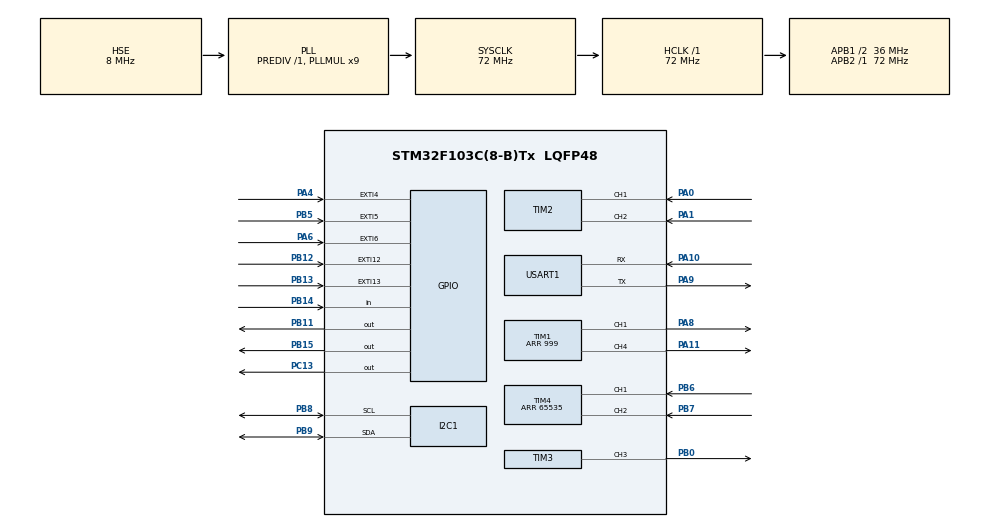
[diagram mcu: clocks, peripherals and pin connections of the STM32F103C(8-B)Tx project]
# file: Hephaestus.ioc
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FREERTOS.Tasks01=defaultTask,24,128,StartDefaultTask,Default,NULL,Dynamic,NULL,NULL
FREERTOS.configTOTAL_HEAP_SIZE=10240
I2C1.I2C_Mode=I2C_Standard
IWDG.Prescaler=IWDG_PRESCALER_32
IWDG.Reload=625
Mcu.Family=STM32F1
Mcu.Name=STM32F103C(8-B)Tx
Mcu.Package=LQFP48
NVIC.EXTI15_10_IRQn=true\:5\:0\:false\:false\:true\:false\:true\:true\:true
NVIC.EXTI4_IRQn=true\:5\:0\:false\:false\:true\:false\:true\:true\:true
NVIC.EXTI9_5_IRQn=true\:5\:0\:false\:false\:true\:false\:true\:true\:true
NVIC.PriorityGroup=NVIC_PRIORITYGROUP_4
PA0-WKUP.Signal=S_TIM2_CH1_ETR
PA1.Signal=S_TIM2_CH2
PA10.Mode=Asynchronous
PA10.Signal=USART1_RX
PA11.Signal=S_TIM1_CH4
PA13.Mode=Serial_Wire
PA13.Signal=SYS_JTMS-SWDIO
PA14.Mode=Serial_Wire
PA14.Signal=SYS_JTCK-SWCLK
PA4.GPIO_PuPd=GPIO_PULLUP
PA4.Signal=GPXTI4
PA6.GPIO_PuPd=GPIO_PULLUP
PA6.Signal=GPXTI6
PA8.Signal=S_TIM1_CH1
PA9.Mode=Asynchronous
PA9.Signal=USART1_TX
PB0.Signal=S_TIM3_CH3
PB11.Signal=GPIO_Output
PB12.GPIO_PuPd=GPIO_PULLUP
PB12.Signal=GPXTI12
PB13.GPIO_PuPd=GPIO_PULLUP
PB13.Signal=GPXTI13
PB14.GPIO_PuPd=GPIO_NOPULL
PB14.Signal=GPIO_Input
PB15.Signal=GPIO_Output
PB5.Signal=GPXTI5
PB6.Signal=S_TIM4_CH1
PB7.Signal=S_TIM4_CH2
PB8.Mode=I2C
PB8.Signal=I2C1_SCL
PB9.Mode=I2C
PB9.Signal=I2C1_SDA
PC13-TAMPER-RTC.Signal=GPIO_Output
PD0-OSC_IN.Mode=HSE-External-Oscillator
PD0-OSC_IN.Signal=RCC_OSC_IN
PD1-OSC_OUT.Mode=HSE-External-Oscillator
PD1-OSC_OUT.Signal=RCC_OSC_OUT
ProjectManager.HeapSize=0x200
ProjectManager.StackSize=0x400
ProjectManager.TargetToolchain=CMake
RCC.AHBFreq_Value=72000000
RCC.APB1CLKDivider=RCC_HCLK_DIV2
RCC.APB1Freq_Value=36000000
RCC.APB1TimFreq_Value=72000000
RCC.APB2Freq_Value=72000000
RCC.APB2TimFreq_Value=72000000
RCC.HCLKFreq_Value=72000000
RCC.PLLMUL=RCC_PLL_MUL9
RCC.PLLSourceVirtual=RCC_PLLSOURCE_HSE
RCC.SYSCLKFreq_VALUE=72000000
RCC.SYSCLKSource=RCC_SYSCLKSOURCE_PLLCLK
RCC.USBFreq_Value=72000000
SH.S_TIM1_CH1.0=TIM1_CH1,PWM Generation1 CH1
SH.S_TIM1_CH4.0=TIM1_CH4,PWM Generation4 CH4
SH.S_TIM2_CH1_ETR.0=TIM2_CH1,Encoder_Interface
SH.S_TIM2_CH2.0=TIM2_CH2,Encoder_Interface
SH.S_TIM3_CH3.0=TIM3_CH3,PWM Generation3 CH3
SH.S_TIM4_CH1.0=TIM4_CH1,Encoder_Interface
SH.S_TIM4_CH2.0=TIM4_CH2,Encoder_Interface
TIM1.Channel-PWM\ Generation1\ CH1=TIM_CHANNEL_1
TIM1.Channel-PWM\ Generation4\ CH4=TIM_CHANNEL_4
TIM1.Period=999
TIM2.EncoderMode=TIM_ENCODERMODE_TI12
TIM3.Channel-PWM\ Generation3\ CH3=TIM_CHANNEL_3
TIM3.Period=249
TIM3.Prescaler=71
TIM4.EncoderMode=TIM_ENCODERMODE_TI12
TIM4.Period=65535
USART1.VirtualMode=VM_ASYNC
VP_FREERTOS_VS_CMSIS_V2.Mode=CMSIS_V2
VP_IWDG_VS_IWDG.Mode=IWDG_Activate
board=custom

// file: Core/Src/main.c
/* USER CODE BEGIN Header */
/**
  ******************************************************************************
  * @file           : main.c
  * @brief          : Main program body
  ******************************************************************************
  * @attention
  *
  * Copyright (c) 2026 STMicroelectronics.
  * All rights reserved.
  *
  * This software is licensed under terms that can be found in the LICENSE file
  * in the root directory of this software component.
  * If no LICENSE file comes with this software, it is provided AS-IS.
  *
  ******************************************************************************
  */
/* USER CODE END Header */
#include "main.h"
#include "cmsis_os.h"
#include "i2c.h"
#include "iwdg.h"
#include "tim.h"
#include "usart.h"
#include "gpio.h"

/* USER CODE BEGIN Includes */
#include "app.hpp"
/* USER CODE END Includes */

void SystemClock_Config(void);
void MX_FREERTOS_Init(void);

int main(void)
{

  /* MCU Configuration--------------------------------------------------------*/

  /* Reset of all peripherals, Initializes the Flash interface and the Systick. */
  HAL_Init();

  /* Configure the system clock */
  SystemClock_Config();

  /* Initialize all configured peripherals */
  MX_GPIO_Init();
  MX_I2C1_Init();
  MX_TIM1_Init();
  MX_TIM2_Init();
  MX_TIM3_Init();
  MX_TIM4_Init();
  MX_USART1_UART_Init();
  MX_IWDG_Init();
  /* USER CODE BEGIN 2 */
  app_setup();
  /* USER CODE END 2 */

  /* Init scheduler */
  osKernelInitialize();  /* Call init function for freertos objects (in cmsis_os2.c) */
  MX_FREERTOS_Init();

  /* Start scheduler */
  osKernelStart();

  /* We should never get here as control is now taken by the scheduler */

  /* Infinite loop */
  while (1)
  {

  }
}

void SystemClock_Config(void)
{
  RCC_OscInitTypeDef RCC_OscInitStruct = {0};
  RCC_ClkInitTypeDef RCC_ClkInitStruct = {0};

  /** Initializes the RCC Oscillators according to the specified parameters
  * in the RCC_OscInitTypeDef structure.
  */
  RCC_OscInitStruct.OscillatorType = RCC_OSCILLATORTYPE_LSI|RCC_OSCILLATORTYPE_HSE;
  RCC_OscInitStruct.HSEState = RCC_HSE_ON;
  RCC_OscInitStruct.HSEPredivValue = RCC_HSE_PREDIV_DIV1;
  RCC_OscInitStruct.HSIState = RCC_HSI_ON;
  RCC_OscInitStruct.LSIState = RCC_LSI_ON;
  RCC_OscInitStruct.PLL.PLLState = RCC_PLL_ON;
  RCC_OscInitStruct.PLL.PLLSource = RCC_PLLSOURCE_HSE;
  RCC_OscInitStruct.PLL.PLLMUL = RCC_PLL_MUL9;
  if (HAL_RCC_OscConfig(&RCC_OscInitStruct) != HAL_OK)
  {
    Error_Handler();
  }

  /** Initializes the CPU, AHB and APB buses clocks
  */
  RCC_ClkInitStruct.ClockType = RCC_CLOCKTYPE_HCLK|RCC_CLOCKTYPE_SYSCLK
                              |RCC_CLOCKTYPE_PCLK1|RCC_CLOCKTYPE_PCLK2;
  RCC_ClkInitStruct.SYSCLKSource = RCC_SYSCLKSOURCE_PLLCLK;
  RCC_ClkInitStruct.AHBCLKDivider = RCC_SYSCLK_DIV1;
  RCC_ClkInitStruct.APB1CLKDivider = RCC_HCLK_DIV2;
  RCC_ClkInitStruct.APB2CLKDivider = RCC_HCLK_DIV1;

  if (HAL_RCC_ClockConfig(&RCC_ClkInitStruct, FLASH_LATENCY_2) != HAL_OK)
  {
    Error_Handler();
  }
}

void Error_Handler(void)
{
  __disable_irq();
  while (1)
  {
  }
}

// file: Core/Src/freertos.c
/* USER CODE BEGIN Header */
/**
  ******************************************************************************
  * File Name          : freertos.c
  * Description        : Code for freertos applications
  ******************************************************************************
  * @attention
  *
  * Copyright (c) 2026 STMicroelectronics.
  * All rights reserved.
  *
  * This software is licensed under terms that can be found in the LICENSE file
  * in the root directory of this software component.
  * If no LICENSE file comes with this software, it is provided AS-IS.
  *
  ******************************************************************************
  */
/* USER CODE END Header */

#include "FreeRTOS.h"
#include "task.h"
#include "main.h"
#include "cmsis_os.h"

/* USER CODE BEGIN Includes */
#include "app.hpp"
/* USER CODE END Includes */

/* Definitions for defaultTask */
osThreadId_t defaultTaskHandle;
const osThreadAttr_t defaultTask_attributes = {
  .name = "defaultTask",
  .stack_size = 128 * 4,
  .priority = (osPriority_t) osPriorityNormal,
};

void StartDefaultTask(void *argument);

void MX_FREERTOS_Init(void); /* (MISRA C 2004 rule 8.1) */

void MX_FREERTOS_Init(void) {

  /* Create the thread(s) */
  /* creation of defaultTask */
  defaultTaskHandle = osThreadNew(StartDefaultTask, NULL, &defaultTask_attributes);

}

void StartDefaultTask(void *argument)
{
  /* USER CODE BEGIN StartDefaultTask */
  /* Infinite loop */
  for(;;)
  {
    //app_loop();
    osDelay(1);
  }
  /* USER CODE END StartDefaultTask */
}
